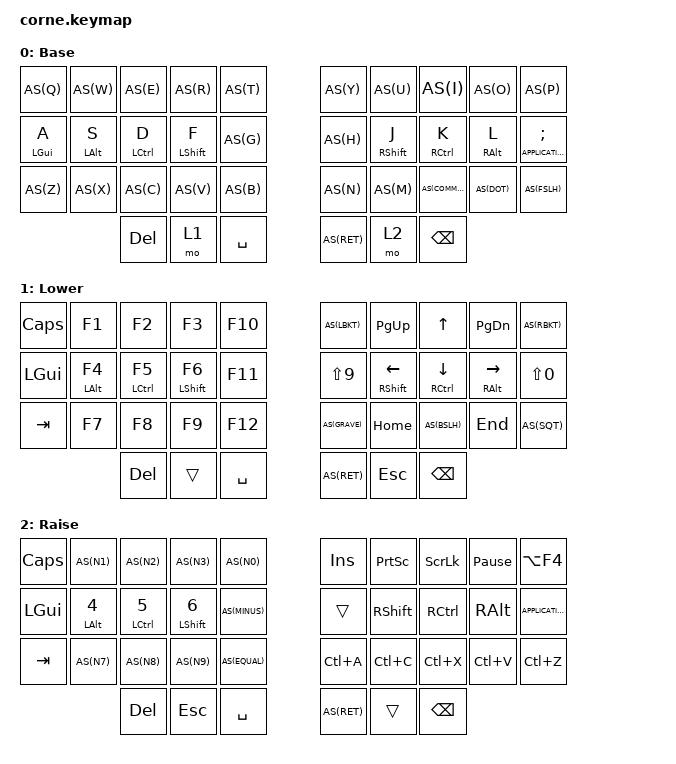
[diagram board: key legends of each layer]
/*
 * Copyright (c) 2020 The ZMK Contributors
 *
 * SPDX-License-Identifier: MIT
 */

#include <behaviors.dtsi>
#include <dt-bindings/zmk/keys.h>
#include <dt-bindings/zmk/bt.h>


#define AS(keycode) &as LS(keycode) keycode

/ {
    chosen {
        zmk,physical-layout = &foostan_corne_5col_layout;
    };

    behaviors {
					as: auto_shift {
				compatible = "zmk,behavior-hold-tap";
				#binding-cells = <2>;
				tapping-term-ms = <250>;
				quick-tap-ms = <0>;
				flavor = "tap-preferred";
				bindings = <&kp>, <&kp>;
			};

			hm: homerow_mods {
				compatible = "zmk,behavior-hold-tap";
				#binding-cells = <2>;
				tapping-term-ms = <250>;
				quick-tap-ms = <175>;
				require-prior-idle-ms = <125>;
				flavor = "balanced";
				bindings = <&kp>, <&kp>;
			};
    };
        keymap {
                compatible = "zmk,keymap";

                default_layer {
// ----------------------------------------------------------------------------------------- 
// |  Q   |  W   |  E   |  R   |  T   |     |  Y   |  U   |  I   |  O   |  P   |
// |  A   |  S   |  D   |  F   |  G   |     |  H   |  J   |  K   |  L   |  ;:  |
// |  Z   |  X   |  C   |  V   |  B   |     |  N   |  M   |  ,<  |  .>  |  /?  |
// 	             | RALT | LWR  | SPC  |     | ENT  | RSE  | BSPC |
                        display-name = "Base";
                        bindings = <
   AS(Q) 		AS(W) 		AS(E) 		AS(R) 		AS(T)     AS(Y)   	AS(U)  			AS(I)		    	AS(O)     		AS(P)
   &hm LGUI A 	&hm LALT S 	&hm LCTRL D &hm LSHFT F AS(G)     AS(H) 	&hm RSHFT J 	&hm RCTRL K 		&hm RALT L 		&hm K_APPLICATION SEMI
   AS(Z) 		AS(X) 		AS(C) 		AS(V) 		AS(B)     AS(N)   	AS(M)  			AS(COMMA) 			AS(DOT)		  	AS(FSLH)
        &kp DEL &mo 1 &kp SPACE     AS(RET) &mo 2  	&kp BSPC
                        >;
                };

                lower_layer {
// ----------------------------------------------------------------------------------------- 
// | TAB  |  F1  |  F2  |  F3  | F10  |     |  [{  | HOME |  UP  | PGUP |  ]}  |
// | LGUI | F4 | F5 | F6 | F11 |     |  (  | LEFT | DOWN | RGHT |  )  |
// | LSFT |  F7  |  F8  |  F9  | F12  |     | `~   | END  |  \|  | PGDN |  '"  |
//               | LGUI |      | TAB  |     | LALT | ESC  | LCTL |
                        display-name = "Lower";
                        bindings = <
    &kp CAPS 	&kp F1      	&kp F2			&kp F3     		&kp F10	        	AS(LBKT)	&kp PG_UP 		&kp UP         	&kp PG_DN	 	AS(RBKT)
    &kp LGUI  	&hm LALT F4  	&hm LCTRL F5  	&hm LSHFT F6  	&kp F11      		&kp LS(N9)  &hm RSHFT LEFT  &hm RCTRL DOWN	&hm RALT RIGHT  &kp LS(N0)
	&kp TAB		&kp F7      	&kp F8      	&kp F9	   		&kp F12        		AS(GRAVE)	&kp HOME  		AS(BSLH)       	&kp END  	 	AS(SQT)
								&kp DEL   		&trans     		&kp SPACE 			AS(RET)  	&kp ESC   		&kp BSPC
                        >;
                };

                raise_layer {
// -----------------------------------------------------------------------------------------
// | TAB  | 1!   | 2@   | 3#   | 0)   |     |      | PSCR | SLCK | PAUS |      |
// | CAPS | 4$   | 5%   | 6^   | -_   |     |S-SAVE| TAB  | LALT |S-TAB | CAD  |
// | LSFT | 7&   | 8*   | 9(   | =+   |     | C-A  | C-C  | C-X  | C-V  | C-Z  |
//               | LGUI | ESC  | TAB  |     | LALT |      | LCTL |
                        display-name = "Raise";
                        bindings = <
   &kp CAPS		AS(N1)			AS(N2)    		AS(N3)  		AS(N0)        	&kp INS		&kp PSCRN		&kp SLCK		&kp PAUSE_BREAK	&kp LA(F4)
   &kp LGUI 	&hm LALT N4		&hm LCTRL N5 	&hm LSHFT N6	AS(MINUS)   	&trans		&kp RSHFT 		&kp RCTRL 		&kp RALT 		&kp K_APPLICATION
   &kp TAB 		AS(N7)			AS(N8)			AS(N9)    		AS(EQUAL)  		&kp LC(A)	&kp LC(C)		&kp LC(X)		&kp LC(V)		&kp LC(Z)
								&kp DEL  		&kp ESC   		&kp SPACE   	AS(RET)  	&trans    		&kp BSPC
                        >;
                };

                extra_1 {
                        status = "reserved";
                };

                extra_2 {
                        status = "reserved";
                };

                extra_3 {
                        status = "reserved";
                };
        };
};
